# STM32H573 register map
File version: 1.7
CPU: CM33 r0p0, little endian, MPU, FPU, 4 interrupt priority bits
Registers are 32-bit, read-write, reset 0x0 unless marked. A register's access mark holds for its fields unless they carry their own. Offsets are from the block's base; [hi:lo] are bit positions; 'fields as' and 'values as' point back to an identical list.

## FLASH (part 1 of 2) — FLASH address block description
Base 0x40022000
Same registers: SEC_FLASH 0x50022000
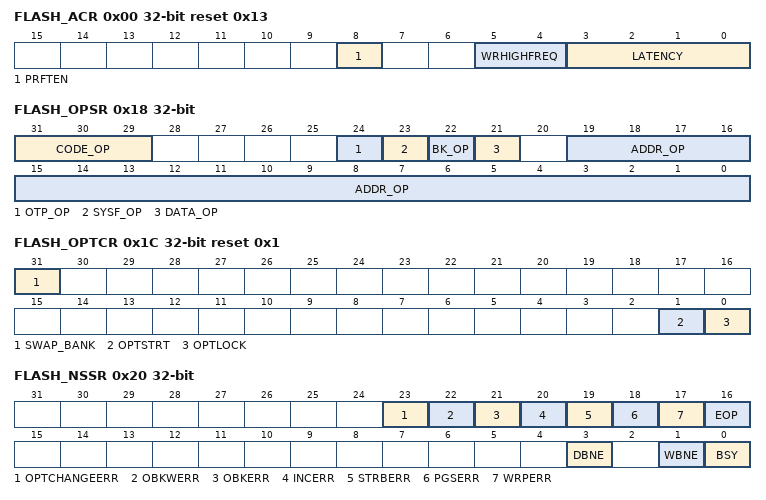
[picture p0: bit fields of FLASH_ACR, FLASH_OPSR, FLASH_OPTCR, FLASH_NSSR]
0x00 FLASH_ACR reset 0x13 — FLASH access control register
  [8] PRFTEN — Prefetch enable. When bit value is modified, user must read back ACR register to be sure PRFTEN has been taken into account. Bits used to control the prefetch.
    0=prefetch disabled; 1=prefetch enabled when latency is at least one wait state
  [5:4] WRHIGHFREQ — Flash signal delay These bits are used to control the delay between nonvolatile memory signals during programming operations. Application software has to program them to the correct value depending on the embedded flash memory interface frequency. Please refer to Table44 for details. Note: No check is performed to verify that the configuration is correct. Note: Two WRHIGHFREQ values can be selected for some frequencies.
  [3:0] LATENCY — Read latency These bits are used to control the number of wait states used during read operations on both nonvolatile memory banks. The application software has to program them to the correct value depending on the embedded flash memory interface frequency and voltage conditions. ... Note: No check is performed by hardware to verify that the configuration is correct.
    0=zero wait states used to read a word from nonvolatile memory; 1=one wait state used to read a word from nonvolatile memory; 2=two wait states used to read a word from nonvolatile memory; 7=seven wait states used to read a word from nonvolatile memory; 15=15 wait states used to read a word from nonvolatile memory
0x04 FLASH_NSKEYR wo — FLASH non-secure key register
  [31:0] NSKEY — Non-volatile memory non-secure configuration access unlock key
0x08 FLASH_SECKEYR wo — FLASH secure key register
  [31:0] SECKEY — Non-volatile memory secure configuration access unlock key
0x0C FLASH_OPTKEYR wo — FLASH option key register
  [31:0] OPTKEY — FLASH option bytes control access unlock key
0x10 FLASH_NSOBKKEYR wo — FLASH non-secure OBK key register
  [31:0] NSOBKKEY — FLASH non-secure option bytes keys control access unlock key
0x14 FLASH_SECOBKKEYR wo — FLASH secure OBK key register
  [31:0] SECOBKKEY — FLASH secure option bytes keys control access unlock key
0x18 FLASH_OPSR ro reset not defined — FLASH operation status register
  [31:29] CODE_OP — Flash memory operation code
    0=No flash operation on going during previous reset; 1=Single write operation interrupted; 2=OBK alternate sector erase; 3=Sector erase operation interrupted; 4=Bank erase operation interrupted; 5=Mass erase operation interrupted; 6=Option change operation interrupted; 7=OBK swap sector request
  [24] OTP_OP — OTP operation interrupted Indicates that reset interrupted an ongoing operation in OTP area (or OBKeys area).
  [23] SYSF_OP — Operation in system flash memory interrupted Indicates that reset interrupted an ongoing operation in system flash.
  [22] BK_OP — Interrupted operation bank It indicates which bank was concerned by operation.
  [21] DATA_OP — Flash high-cycle data area operation interrupted It indicates if flash high-cycle data area is concerned by operation.
  [19:0] ADDR_OP — Interrupted operation address
0x1C FLASH_OPTCR access per field reset 0x1 (reset mask 0xFFFFFFF) — FLASH option control register
  [31] SWAP_BANK ro — Bank swapping option configuration bit SWAP_BANK controls whether Bank1 and Bank2 are swapped or not. This bit is loaded with the SWAP_BANK bit of FLASH_OPTSR_CUR register only after reset or POR.
    0=Bank1 and Bank2 not swapped; 1=Bank1 and Bank2 swapped
  [1] OPTSTRT rw — Option byte start change option configuration bit OPTSTRT triggers an option byte change operation. The user can set OPTSTRT only when the OPTLOCK bit is cleared to 0. It is set only by Software and cleared when the option byte change is completed or an error occurs (PGSERR or OPTCHANGEERR). It is reseted at the same time as BSY bit. The user application cannot modify any FLASH_XXX_PRG flash interface register until the option change operation has been completed. Before setting this bit, the user has to write the required values in the FLASH_XXX_PRG registers. The FLASH_XXX_PRG registers are locked until the option byte change operation has been executed in nonvolatile memory.
  [0] OPTLOCK rw — FLASH_OPTCR lock option configuration bit The OPTLOCK bit locks the FLASH_OPTCR register as well as all _PRG registers. The correct write sequence to FLASH_OPTKEYR register unlocks this bit. If a wrong sequence is executed, or the unlock sequence to FLASH_OPTKEYR is performed twice, this bit remains locked until next system reset. It is possible to set OPTLOCK by programming it to 1. When set to 1, a new unlock sequence is mandatory to unlock it. When OPTLOCK changes from 0 to 1, the others bits of FLASH_OPTCR register do not change.
    0=FLASH_OPTCR register unlocked; 1=FLASH_OPTCR register locked
0x20 FLASH_NSSR ro (reset mask 0xFFFFFFF0) — FLASH non-secure status register
  [23] OPTCHANGEERR — Option byte change error flag OPTCHANGEERR flag indicates that an error occurred during an option byte change operation. When OPTCHANGEERR is set to 1, the option byte change operation did not successfully complete. An interrupt is generated when this flag is raised if the OPTCHANGEERRIE bit of FLASH_NSCR register is set to 1. Writing 1 to CLR_OPTCHANGEERR of register FLASH_NSCCR clears OPTCHANGEERR. Note: The OPTSTRT bit in FLASH_OPTCR cannot be set while OPTCHANGEERR is set.
    0=no option byte change errors occurred; 1=one or more errors occurred during an option byte change operation
  [22] OBKWERR — OBK write error flag OBKWERR flag is raised when the address is not virgin on a write access to the OBK storage. Alternatively also when the OBK selector in the alternate sector is not virgin during a swap operation.
    0=no OBK write error occurred; 1=an OBK write error occurred
  [21] OBKERR — OBK general error flag OBKERR flag is raised when the OBK-HDPL signal from the SBS does not match the HDPL value associated with the key slot during access to the key location. Alternatively also when the ALT_SECT is unexpectedly changed while the write buffer is being filled.
    0=no OBK general error occurred; 1=an OBK general error occurred
  [20] INCERR — inconsistency error flag NSINCERR flag is raised when a inconsistency error occurs. An interrupt is generated if INCERRIE is set to 1. Writing 1 to CLR_INCERR bit in the FLASH_NSCCR register clears NSINCERR.
    0=no inconsistency error occurs; 1=a inconsistency error occurs
  [19] STRBERR — strobe error flag STRBERR flag is raised when a strobe error occurs (when the master attempts to write several times the same byte in the write buffer). An interrupt is generated if the STRBERRIE bit is set to 1. Writing 1 to CLR_STRBERR bit in FLASH_NSCCR register clears STRBERR.
    0=no strobe error occurred; 1=a strobe error occurred
  [18] PGSERR — programming sequence error flag PGSERR flag is raised when a sequence error occurs. An interrupt is generated if the PGSERRIE bit is set to 1. Writing 1 to CLR_PGSERR bit in FLASH_NSCCR register clears PGSERR.
    0=no sequence error occurred; 1=a sequence error occurred
  [17] WRPERR — write protection error flag WRPERR flag is raised when a protection error occurs during a program operation. An interrupt is also generated if the WRPERRIE is set to 1. Writing 1 to CLR_WRPERR bit in FLASH_NSCCR register clears WRPERR.
    0=no write protection error occurred; 1=a write protection error occurred
  [16] EOP — end of operation flag EOP flag is set when a operation (program/erase) completes. An interrupt is generated if the EOPIE is set to 1. It is not necessary to reset EOP before starting a new operation. EOP bit is cleared by writing 1 to CLR_EOP bit in FLASH_NSCCR register.
    0=no operation completed; 1=a operation completed
  [3] DBNE — data buffer not empty flag DBNE flag is set when the flash interface is processing 6-bits ECC data in dedicated buffer. This bit cannot be set to 0 by software. The hardware resets it once the buffer is free.
    0=data buffer not used; 1=data buffer used, wait
  [1] WBNE — write buffer not empty flag WBNE flag is set when the flash interface is waiting for new data to complete the write buffer. In this state, the write buffer is not empty. WBNE is reset by hardware each time the write buffer is complete or the write buffer is emptied following one of the event below: the application software forces the write operation using FW bit in FLASH_NSCR the embedded flash memory detects an error that involves data loss This bit cannot be reset by software writing 0 directly. To reset it, clear the write buffer by performing any of the above listed actions, or send the missing data.
    0=write buffer empty or full; 1=write buffer waiting data to complete
  [0] BSY — busy flag BSY flag indicates that a flash memory is busy by an operation (write, erase, option byte change, OBK operation). It is set at the beginning of a flash memory operation and cleared when the operation finishes, or an error occurs.
    0=no programming, erase or option byte change operation being executed; 1=programming, erase or option byte change operation being executed
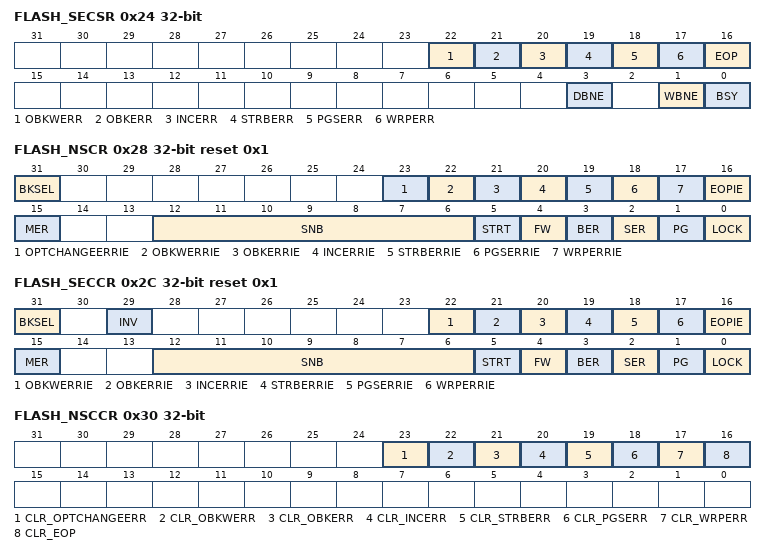
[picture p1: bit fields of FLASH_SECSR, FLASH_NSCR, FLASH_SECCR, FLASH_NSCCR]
0x24 FLASH_SECSR ro (reset mask 0xFFFFFFF0) — FLASH secure status register
  [22] OBKWERR — OBK write error flag OBKWERR flag is raised when the address is not virgin on a write access to the OBK storage. Alternatively also when the OBK selector in the alternate sector is not virgin during a swap operation.
    0=no OBK write error occurred; 1=an OBK write error occurred
  [21] OBKERR — OBK general error flag OBKERR flag is raised when the OBK-HDPL signal from the SBS does not match the HDPL value associated with the key slot during access to the key location. Alternatively also when the ALT_SECT is unexpectedly changed while the write buffer is being filled.
    values as FLASH_NSSR.OBKERR
  [20] INCERR — inconsistency error flag INCERR flag is raised when a inconsistency error occurs. An interrupt is generated if INCERRIE is set to 1. Writing 1 to CLR_INCERR bit in the FLASH_SECCCR register clears INCERR.
    0=no inconsistency error occurred; 1=a inconsistency error occurred
  [19] STRBERR — strobe error flag STRBERR flag is raised when a strobe error occurs (when the master attempts to write several times the same byte in the write buffer). An interrupt is generated if the STRBERRIE bit is set to 1. Writing 1 to CLR_STRBERR bit in FLASH_SECCCR register clears STRBERR.
    0=no strobe error occurred; 1=a strobe error occurred
  [18] PGSERR — programming sequence error flag PGSERR flag is raised when a sequence error occurs. An interrupt is generated if the PGSERRIE bit is set to 1. Writing 1 to CLR_PGSERR bit in FLASH_SECCCR register clears PGSERR.
    0=no sequence error occurred; 1=a sequence error occurred
  [17] WRPERR — write protection error flag WRPERR flag is raised when a protection error occurs during a program operation. An interrupt is also generated if the WRPERRIE is set to 1. Writing 1 to CLR_WRPERR bit in FLASH_SECCCR register clears WRPERR.
    values as FLASH_NSSR.WRPERR
  [16] EOP — end of operation flag EOP flag is set when a operation (program/erase) completes. An interrupt is generated if the EOPIE is set to. It is not necessary to reset EOP before starting a new operation. EOP bit is cleared by writing 1 to CLR_EOP bit in FLASH_SECCCR register.
    0=no operation completed; 1=a operation completed
  [3] DBNE — data buffer not empty flag DBNE flag is set when the embedded flash memory interface is processing 6-bits ECC data in dedicated buffer. This bit cannot be set to 0 by software. The hardware resets it once the buffer is free.
    0=data buffer not used; 1=data buffer used, wait
  [1] WBNE — write buffer not empty flag WBNE flag is set when the flash interface is waiting for new data to complete the write buffer. In this state, the write buffer is not empty. WBNE is reset by hardware each time the write buffer is complete or the write buffer is emptied following one of the event below: the application software forces the write operation using FW bit in FLASH_SECCR the flash interface detects an error that involves data loss This bit cannot be reset by writing 0 directly by software. To reset it, clear the write buffer by performing any of the above listed actions, or send the missing data.
    values as FLASH_NSSR.WBNE
  [0] BSY — busy flag BSY flag indicates that a FLASH memory is busy (write, erase, option byte change, OBK operations). It is set at the beginning of a flash memory operation and cleared when the operation finishes or an error occurs.
    values as FLASH_NSSR.BSY
0x28 FLASH_NSCR reset 0x1 — FLASH non-secure control register
  [31] BKSEL — Bank selector bit BKSEL can only be programmed when LOCK is cleared to 0. The bit selects physical bank, SWAP_BANK setting is ignored.
    0=Bank1 is selected for Bank erase / sector erase / interrupt enable; 1=Bank2 is selected for BER / SER
  [23] OPTCHANGEERRIE — Option byte change error interrupt enable bit This bit controls if an interrupt must be generated when an error occurs during an option byte change. It can be programmed only when LOCK bit is cleared to 0.
    0=no interrupt is generated when an error occurs during an option byte change; 1=an interrupt is generated when and error occurs during an option byte change
  [22] OBKWERRIE — OBK write error interrupt enable bit OBKWERRIE enables generation of interrupt in case of OBK specific write error. This bit can be programmed only when LOCK bit is cleared to 0.
    0=no interrupt is generated on OBK write error; 1=an interrupt is generated on OBK write error
  [21] OBKERRIE — OBK general error interrupt enable bit OBKERRIE enables generating an interrupt in case of OBK specific access error. This bit can be programmed only when LOCK bit is cleared to 0.
    0=no interrupt is generated on OBK general access error; 1=an interrupt is generated on OBK general access error
  [20] INCERRIE — inconsistency error interrupt enable bit When INCERRIE bit is set to 1, an interrupt is generated when an inconsistency error occurs during a write operation. INCERRIE can be programmed only when LOCK is cleared to 0.
    0=no interrupt generated when a inconsistency error occurs; 1=interrupt generated when a inconsistency error occurs
  [19] STRBERRIE — strobe error interrupt enable bit When STRBERRIE bit is set to 1, an interrupt is generated when a strobe error occurs (the master programs several times the same byte in the write buffer) during a write operation. STRBERRIE can be programmed only when LOCK is cleared to 0.
    0=no interrupt generated when a strobe error occurs; 1=interrupt generated when strobe error occurs
  [18] PGSERRIE — programming sequence error interrupt enable bit When this bit is set to 1, an interrupt is generated when a sequence error occurs during a program operation. PGSERRIE can be programmed only when LOCK is cleared to 0.
    0=no interrupt generated when a sequence error occurs; 1=interrupt generated when sequence error occurs
  [17] WRPERRIE — write protection error interrupt enable bit When this bit is set to 1, an interrupt is generated when a protection error occurs during a program operation. WRPERRIE can be programmed only when LOCK is cleared to 0.
    0=no interrupt generated when a protection error occurs; 1=interrupt generated when a protection error occurs
  [16] EOPIE — end of operation interrupt control bit Setting EOPIE bit to 1 enables the generation of an interrupt at the end of a program or erase operation. EOPIE can be programmed only when LOCK is cleared to 0.
    0=no interrupt generated at the end of operation; 1=interrupt enabled when at the end of operation
  [15] MER — Mass erase request Setting MER bit to 1 requests a mass erase operation (user flash memory only). MER can be programmed only when LOCK is cleared to 0. If BER or SER are both set, a PGSERR is raised. Error is triggered when a mass erase is required and some sectors are protected.
    0=mass erase not requested; 1=mass erase requested
  [12:6] SNB — sector erase selection number These bits are used to select the target sector for an erase operation (they are unused otherwise). SNB can be programmed only when LOCK is cleared to 0. ..
    0=Sector 0 selected; 1=Sector 1 selected; 127=Sector 127 selected
  [5] STRT — erase start control bit STRT bit is used to start a sector erase or a bank erase operation. STRT can be programmed only when LOCK is cleared to 0. STRT is reset at the end of the operation or when an error occurs. It cannot be reseted by software.
  [4] FW — write forcing control bit FW forces a write operation even if the write buffer is not full. In this case all bits not written are set to 1 by hardware. FW can be programmed only when LOCK is cleared to 0. The embedded flash memory resets FW when the corresponding operation has been acknowledged. Note: Using a force-write operation prevents the application from updating later the missing bits with something else than 1, because it is likely that it leads to permanent ECC error. Write forcing is effective only if the write buffer is not empty and was filled by non-secure access (in particular, FW does not start several write operations when the force-write operations are performed consecutively). Since there is just one write buffer, FW can force a write in bank1 or bank2.
  [3] BER — erase request Setting BER bit to 1 requests a bank erase operation (user flash memory only). BER can be programmed only when LOCK is cleared to 0. If MER and SER are also set, a PGSERR is raised. Note: Write protection error is triggered when a bank erase is required and some sectors are protected.
    0=bank erase not requested; 1=bank erase requested
  [2] SER — sector erase request Setting SER bit to 1 requests a sector erase. SER can be programmed only when LOCK is cleared to 0. If MER and SER are also set, a PGSERR is raised.
    0=sector erase not requested; 1=sector erase requested
  [1] PG — programming control bit PG can be programmed only when LOCK is cleared to 0. PG allows programming in Bank1 and Bank2.
    0=programming disabled; 1=programming enabled
  [0] LOCK — configuration lock bit This bit locks the FLASH_NSCR register. The correct write sequence to FLASH_NSKEYR register unlocks this bit. If a wrong sequence is executed, or if the unlock sequence to FLASH_NSKEYR is performed twice, this bit remains locked until the next system reset. LOCK can be set by programming it to 1. When set to 1, a new unlock sequence is mandatory to unlock it. When LOCK changes from 0 to 1, the other bits of FLASH_NSCR register do not change.
    0=FLASH_NSCR register unlocked; 1=FLASH_NSCR register locked
0x2C FLASH_SECCR reset 0x1 — FLASH secure control register
  [31] BKSEL — bank selector bit BKSEL can only be programmed when LOCK is cleared to 0. The bit selects physical bank, SWAP_BANK setting is ignored.
    values as FLASH_NSCR.BKSEL
  [29] INV — Flash memory security state invert. This bit inverts the flash memory security state.
  [22] OBKWERRIE — OBK write error interrupt enable bit OBKWERRIE enables generation of interrupt in case of OBK specific write error. OBKWERRIE can be programmed only when LOCK is cleared to 0.
    values as FLASH_NSCR.OBKWERRIE
  [21] OBKERRIE — OBK general error interrupt enable bit OBKERRIE enables generating an interrupt in case of OBK specific access error. OBKERRIE can be programmed only when LOCK is cleared to 0.
    values as FLASH_NSCR.OBKERRIE
  [20] INCERRIE — inconsistency error interrupt enable bit When INCERRIE bit is set to 1, an interrupt is generated when an inconsistency error occurs during a write operation. INCERRIE can be programmed only when LOCK is cleared to 0.
    values as FLASH_NSCR.INCERRIE
  [19] STRBERRIE — strobe error interrupt enable bit When STRBERRIE bit is set to 1, an interrupt is generated when a strobe error occurs (the master programs several times the same byte in the write buffer) during a write operation. STRBERRIE can be programmed only when LOCK is cleared to 0.
    values as FLASH_NSCR.STRBERRIE
  [18] PGSERRIE — programming sequence error interrupt enable bit When PGSERRIE bit is set to 1, an interrupt is generated when a sequence error occurs during a program operation. PGSERRIE can be programmed only when LOCK is cleared to 0.
    values as FLASH_NSCR.PGSERRIE
  [17] WRPERRIE — write protection error interrupt enable bit When WRPERRIE bit is set to 1, an interrupt is generated when a protection error occurs during a program operation. WRPERRIE can be programmed only when LOCK is cleared to 0.
    values as FLASH_NSCR.WRPERRIE
  [16] EOPIE — end of operation interrupt control bit Setting EOPIE bit to 1 enables the generation of an interrupt at the end of a program/erase operation. EOPIE can be programmed only when LOCK is cleared to 0.
    values as FLASH_NSCR.EOPIE
  [15] MER — mass erase request Setting MER bit to 1 requests a mass erase operation (user flash memory only). MER can be programmed only when LOCK is cleared to 0. If BER or SER are also set, a PGSERR is raised. Error is triggered when a mass erase is required and some sectors are protected.
    0=mass erase not requested; 1=mass erase requested
  [12:6] SNB — sector erase selection number These bits are used to select the target sector for an erase operation (they are unused otherwise). SNB can be programmed only when LOCK is cleared to 0. ..
    values as FLASH_NSCR.SNB
  [5] STRT — erase start control bit STRT bit is used to start a sector erase or a bank erase operation. STRT can be programmed only when LOCK is cleared to 0. STRT is reseted at the end of the operation or when an error occurs. It cannot be reset by software.
  [4] FW — write forcing control bit FW forces a write operation even if the write buffer is not full. In this case all bits not written are set to 1 by hardware. FW can be programmed only when LOCK is cleared to 0. The embedded flash memory resets FW when the corresponding operation has been acknowledged. Note: Using a force-write operation prevents the application from updating later the missing bits with something else than 1, because it is likely that it leads to permanent ECC error. Write forcing is effective only if the write buffer is not empty and was filled by secure access (in particular, FW does not start several write operations when the force-write operations are performed consecutively). Since there is just one write buffer, FW can force a write in bank1 or bank2.
  [3] BER — erase request Setting BER bit to 1 requests a bank erase operation (user flash memory only). BER can be programmed only when LOCK is cleared to 0. If MER and SER are also set, a PGSERR is raised. Note: Write protection error is triggered when a bank erase is required and some sectors are protected.
    0=bank erase not requested; 1=bank erase requested
  [2] SER — sector erase request Setting SER bit to 1 requests a sector erase. SER can be programmed only when LOCK is cleared to 0. If BER and MER are also set, a PGSERR is raised.
    0=sector erase not requested; 1=sector erase requested
  [1] PG — programming control bit PG can be programmed only when LOCK is cleared to 0. PG allows programming in Bank1 and Bank2.
    0=programming disabled; 1=programming enabled
  [0] LOCK — configuration lock bit This bit locks the FLASH_SECCR register. The correct write sequence to FLASH_SECKEYR register unlocks this bit. If a wrong sequence is executed, or if the unlock sequence to FLASH_NSKEYR is performed twice, this bit remains locked until the next system reset. LOCK can be set by programming it to 1. When set to 1, a new unlock sequence is mandatory to unlock it. When LOCK changes from 0 to 1, the other bits of FLASH_SECCR register do not change.
    0=FLASH_SECCR register unlocked; 1=FLASH_SECCR register locked
0x30 FLASH_NSCCR wo — FLASH non-secure clear control register
  [23] CLR_OPTCHANGEERR — Clear the flag corresponding flag in FLASH_NSSR by writing this bit.
  [22] CLR_OBKWERR — OBKWERR flag clear bit. Setting this bit to 1 resets to 0 OBKWERR flag in FLASH_NSSR register.
  [21] CLR_OBKERR — OBKERR flag clear bit. Setting this bit to 1 resets to 0 OBKERR flag in FLASH_NSSR register.
  [20] CLR_INCERR — INCERR flag clear bit Setting this bit to 1 resets to 0 INCERR flag in FLASH_NSSR register.
  [19] CLR_STRBERR — STRBERR flag clear bit Setting this bit to 1 resets to 0 STRBERR flag in FLASH_NSSR register.
  [18] CLR_PGSERR — PGSERR flag clear bit Setting this bit to 1 resets to 0 PGSERR flag in FLASH_NSSR register.
  [17] CLR_WRPERR — WRPERR flag clear bit Setting this bit to 1 resets to 0 WRPERR flag in FLASH_NSSR register.
  [16] CLR_EOP — EOP flag clear bit Setting this bit to 1 resets to 0 EOP flag in FLASH_NSSR register.
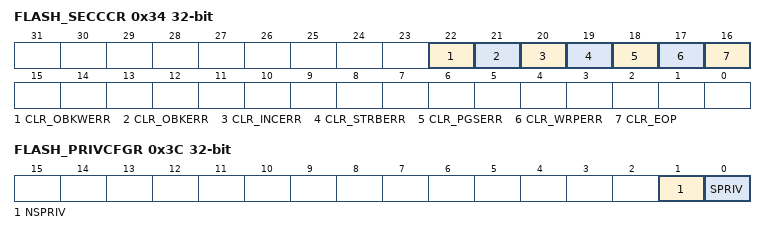
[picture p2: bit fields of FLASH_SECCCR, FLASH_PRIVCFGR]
0x34 FLASH_SECCCR wo — FLASH secure clear control register
  [22] CLR_OBKWERR — OBKWERR flag clear bit Setting this bit to 1 resets to 0 OBKWERR flag in FLASH_SECSR register.
  [21] CLR_OBKERR — OBKWERR flag clear bit Setting this bit to 1 resets to 0 OBKWERR flag in FLASH_SECSR register.
  [20] CLR_INCERR — INCERR flag clear bit Setting this bit to 1 resets to 0 INCERR flag in FLASH_SECSR register.
  [19] CLR_STRBERR — STRBERR flag clear bit Setting this bit to 1 resets to 0 STRBERR flag in FLASH_SECSR register.
  [18] CLR_PGSERR — PGSERR flag clear bit Setting this bit to 1 resets to 0 PGSERR flag in FLASH_SECSR register.
  [17] CLR_WRPERR — WRPERR flag clear bit Setting this bit to 1 resets to 0 WRPERR flag in FLASH_SECSR register.
  [16] CLR_EOP — EOP flag clear bit Setting this bit to 1 resets to 0 EOP flag in FLASH_SECSR register.
0x3C FLASH_PRIVCFGR — FLASH privilege configuration register
  [1] NSPRIV — privilege attribute for non secure registers
    0=access to non secure registers is always granted; 1=access to non secure registers is denied in case of unprivileged access
  [0] SPRIV — privilege attribute for secure registers
    0=access to secure registers is always granted; 1=access to secure registers is denied in case of unprivileged access
